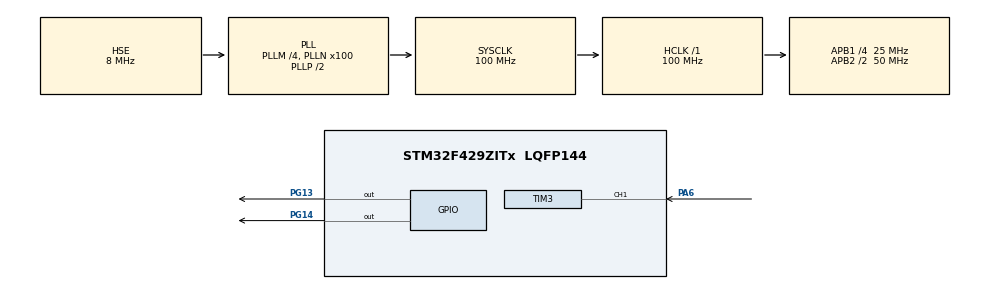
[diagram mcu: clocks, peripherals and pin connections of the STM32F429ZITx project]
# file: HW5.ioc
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Mcu.Family=STM32F4
Mcu.Name=STM32F429ZITx
Mcu.Package=LQFP144
NVIC.PriorityGroup=NVIC_PRIORITYGROUP_4
NVIC.TIM3_IRQn=true\:0\:0\:false\:false\:true\:true\:true
PA6.Signal=S_TIM3_CH1
PG13.GPIO_Speed=GPIO_SPEED_FREQ_VERY_HIGH
PG13.Signal=GPIO_Output
PG14.GPIO_Speed=GPIO_SPEED_FREQ_VERY_HIGH
PG14.Signal=GPIO_Output
PH0/OSC_IN.Mode=HSE-External-Oscillator
PH0/OSC_IN.Signal=RCC_OSC_IN
PH1/OSC_OUT.Mode=HSE-External-Oscillator
PH1/OSC_OUT.Signal=RCC_OSC_OUT
ProjectManager.HeapSize=0x200
ProjectManager.StackSize=0x400
ProjectManager.TargetToolchain=EWARM V8.32
RCC.48MHZClocksFreq_Value=50000000
RCC.AHBFreq_Value=100000000
RCC.APB1CLKDivider=RCC_HCLK_DIV4
RCC.APB1Freq_Value=25000000
RCC.APB1TimFreq_Value=50000000
RCC.APB2CLKDivider=RCC_HCLK_DIV2
RCC.APB2Freq_Value=50000000
RCC.APB2TimFreq_Value=100000000
RCC.CortexFreq_Value=100000000
RCC.HCLKFreq_Value=100000000
RCC.HSE_VALUE=8000000
RCC.HSI_VALUE=16000000
RCC.LSE_VALUE=32768
RCC.PLLM=4
RCC.PLLN=100
RCC.PLLSourceVirtual=RCC_PLLSOURCE_HSE
RCC.SYSCLKFreq_VALUE=100000000
RCC.SYSCLKSource=RCC_SYSCLKSOURCE_PLLCLK
RCC.VCOOutputFreq_Value=200000000
SH.S_TIM3_CH1.0=TIM3_CH1,Input_Capture1_from_TI1
TIM3.Channel-Input_Capture1_from_TI1=TIM_CHANNEL_1
TIM3.Period=0xffff-1
VP_TIM3_VS_ClockSourceINT.Mode=Internal
board=custom

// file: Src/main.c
/* USER CODE BEGIN Header */
/**
  ******************************************************************************
  * @file           : main.c
  * @brief          : Main program body
  ******************************************************************************
  * @attention
  *
  * <h2><center>&copy; Copyright (c) 2020 STMicroelectronics.
  * All rights reserved.</center></h2>
  *
  * This software component is licensed by ST under BSD 3-Clause license,
  * the "License"; You may not use this file except in compliance with the
  * License. You may obtain a copy of the License at:
  *                        opensource.org/licenses/BSD-3-Clause
  *
  ******************************************************************************
  */
/* USER CODE END Header */

#include "main.h"

/* USER CODE BEGIN Includes */
extern float freq;
/* USER CODE END Includes */

TIM_HandleTypeDef htim3;

void SystemClock_Config(void);
static void MX_GPIO_Init(void);
static void MX_TIM3_Init(void);

int main(void)
{

  /* MCU Configuration--------------------------------------------------------*/

  /* Reset of all peripherals, Initializes the Flash interface and the Systick. */
  HAL_Init();

  /* Configure the system clock */
  SystemClock_Config();

  /* Initialize all configured peripherals */
  MX_GPIO_Init();
  MX_TIM3_Init();
  /* USER CODE BEGIN 2 */
  HAL_TIM_IC_Start_IT(&htim3, TIM_CHANNEL_1);
  /* USER CODE END 2 */

  /* Infinite loop */
  /* USER CODE BEGIN WHILE */
  while (1)
  {
     if ((freq < 8000 && freq >= 0) || freq >= 60000)
  {
    HAL_GPIO_WritePin(GPIOG, GPIO_PIN_13,1);
    HAL_GPIO_WritePin(GPIOG, GPIO_PIN_14,1);
  }
    else if (freq >= 8000 && freq < 44000)
  {
    HAL_GPIO_WritePin(GPIOG, GPIO_PIN_13,0);
    HAL_GPIO_WritePin(GPIOG, GPIO_PIN_14,1);
  }
   else if( freq >= 44000 && freq < 60000)
  {
    HAL_GPIO_WritePin(GPIOG, GPIO_PIN_13,1);
    HAL_GPIO_WritePin(GPIOG, GPIO_PIN_14,0);
  }
    /* USER CODE END WHILE */

  }
}

void SystemClock_Config(void)
{
  RCC_OscInitTypeDef RCC_OscInitStruct = {0};
  RCC_ClkInitTypeDef RCC_ClkInitStruct = {0};

  /** Configure the main internal regulator output voltage
  */
  __HAL_RCC_PWR_CLK_ENABLE();
  __HAL_PWR_VOLTAGESCALING_CONFIG(PWR_REGULATOR_VOLTAGE_SCALE3);
  /** Initializes the CPU, AHB and APB busses clocks
  */
  RCC_OscInitStruct.OscillatorType = RCC_OSCILLATORTYPE_HSE;
  RCC_OscInitStruct.HSEState = RCC_HSE_ON;
  RCC_OscInitStruct.PLL.PLLState = RCC_PLL_ON;
  RCC_OscInitStruct.PLL.PLLSource = RCC_PLLSOURCE_HSE;
  RCC_OscInitStruct.PLL.PLLM = 4;
  RCC_OscInitStruct.PLL.PLLN = 100;
  RCC_OscInitStruct.PLL.PLLP = RCC_PLLP_DIV2;
  RCC_OscInitStruct.PLL.PLLQ = 4;
  if (HAL_RCC_OscConfig(&RCC_OscInitStruct) != HAL_OK)
  {
    Error_Handler();
  }
  /** Initializes the CPU, AHB and APB busses clocks
  */
  RCC_ClkInitStruct.ClockType = RCC_CLOCKTYPE_HCLK|RCC_CLOCKTYPE_SYSCLK
                              |RCC_CLOCKTYPE_PCLK1|RCC_CLOCKTYPE_PCLK2;
  RCC_ClkInitStruct.SYSCLKSource = RCC_SYSCLKSOURCE_PLLCLK;
  RCC_ClkInitStruct.AHBCLKDivider = RCC_SYSCLK_DIV1;
  RCC_ClkInitStruct.APB1CLKDivider = RCC_HCLK_DIV4;
  RCC_ClkInitStruct.APB2CLKDivider = RCC_HCLK_DIV2;

  if (HAL_RCC_ClockConfig(&RCC_ClkInitStruct, FLASH_LATENCY_3) != HAL_OK)
  {
    Error_Handler();
  }
}

static void MX_TIM3_Init(void)
{

  TIM_ClockConfigTypeDef sClockSourceConfig = {0};
  TIM_MasterConfigTypeDef sMasterConfig = {0};
  TIM_IC_InitTypeDef sConfigIC = {0};

  htim3.Instance = TIM3;
  htim3.Init.Prescaler = 0;
  htim3.Init.CounterMode = TIM_COUNTERMODE_UP;
  htim3.Init.Period = 0xffff-1;
  htim3.Init.ClockDivision = TIM_CLOCKDIVISION_DIV1;
  htim3.Init.AutoReloadPreload = TIM_AUTORELOAD_PRELOAD_DISABLE;
  if (HAL_TIM_Base_Init(&htim3) != HAL_OK)
  {
    Error_Handler();
  }
  sClockSourceConfig.ClockSource = TIM_CLOCKSOURCE_INTERNAL;
  if (HAL_TIM_ConfigClockSource(&htim3, &sClockSourceConfig) != HAL_OK)
  {
    Error_Handler();
  }
  if (HAL_TIM_IC_Init(&htim3) != HAL_OK)
  {
    Error_Handler();
  }
  sMasterConfig.MasterOutputTrigger = TIM_TRGO_RESET;
  sMasterConfig.MasterSlaveMode = TIM_MASTERSLAVEMODE_DISABLE;
  if (HAL_TIMEx_MasterConfigSynchronization(&htim3, &sMasterConfig) != HAL_OK)
  {
    Error_Handler();
  }
  sConfigIC.ICPolarity = TIM_INPUTCHANNELPOLARITY_RISING;
  sConfigIC.ICSelection = TIM_ICSELECTION_DIRECTTI;
  sConfigIC.ICPrescaler = TIM_ICPSC_DIV1;
  sConfigIC.ICFilter = 0;
  if (HAL_TIM_IC_ConfigChannel(&htim3, &sConfigIC, TIM_CHANNEL_1) != HAL_OK)
  {
    Error_Handler();
  }

}

static void MX_GPIO_Init(void)
{
  GPIO_InitTypeDef GPIO_InitStruct = {0};

  /* GPIO Ports Clock Enable */
  __HAL_RCC_GPIOH_CLK_ENABLE();
  __HAL_RCC_GPIOA_CLK_ENABLE();
  __HAL_RCC_GPIOG_CLK_ENABLE();

  /*Configure GPIO pin Output Level */
  HAL_GPIO_WritePin(GPIOG, GPIO_PIN_13|GPIO_PIN_14, GPIO_PIN_RESET);

  /*Configure GPIO pins : PG13 PG14 */
  GPIO_InitStruct.Pin = GPIO_PIN_13|GPIO_PIN_14;
  GPIO_InitStruct.Mode = GPIO_MODE_OUTPUT_PP;
  GPIO_InitStruct.Pull = GPIO_NOPULL;
  GPIO_InitStruct.Speed = GPIO_SPEED_FREQ_VERY_HIGH;
  HAL_GPIO_Init(GPIOG, &GPIO_InitStruct);

}

void Error_Handler(void)
{
}

/************************ (C) COPYRIGHT STMicroelectronics *****END OF FILE****/
